AUTOSAR XML (schema 00046)
package /ComponentTypes
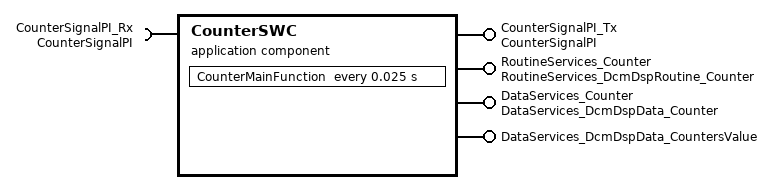
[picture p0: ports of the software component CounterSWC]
  application sw component type CounterSWC
    require port CounterSignalPI_Rx: nonqueued-receiver-com-spec{data-element=Element, filter=data-filter-type=ALWAYS, init-value=0}, required-interface=CounterSignalPI
    4 x provide port:
      CounterSignalPI_Tx: nonqueued-sender-com-spec{data-element=Element, init-value=0}, provided-interface=CounterSignalPI
      RoutineServices_Counter: provided-interface=RoutineServices_DcmDspRoutine_Counter
        provided-com-specs:
          operation=RequestResults, queue-length=1
          operation=Stop, queue-length=1
          operation=Start, queue-length=1
      DataServices_Counter: provided-com-specs=[{operation=WriteData, queue-length=1}, {operation=ReadData, queue-length=1}], provided-interface=DataServices_DcmDspData_Counter
      DataServices_DcmDspData_CountersValue: server-com-spec{operation=ReadData, queue-length=1}, provided-interface=DataServices_DcmDspData_CountersValue
    behavior CounterSWC_InternalBehavior
      data received event DRT_CounterRecieveSignal_CounterSignalPI_Rx_Element: start-on-event=CounterRecieveSignal, data=CounterSignalPI_Rx.Element
      timing event TMT_CounterMainFunction: start-on-event=CounterMainFunction, period=0.025
      6 x operation invoked event:
        OIT_RoutineServices_Counter_RequestResults_RoutineServices_Counter_RequestResults: start-on-event=RoutineServices_Counter_RequestResults, operation=RoutineServices_Counter.RequestResults
        OIT_RoutineServices_Counter_Stop_RoutineServices_Counter_Stop: start-on-event=RoutineServices_Counter_Stop, operation=RoutineServices_Counter.Stop
        OIT_RoutineServices_Counter_Start_RoutineServices_Counter_Start: start-on-event=RoutineServices_Counter_Start, operation=RoutineServices_Counter.Start
        OIT_DataServices_Counter_WriteData_DataServices_Counter_WriteData: start-on-event=DataServices_Counter_WriteData, operation=DataServices_Counter.WriteData
        OIT_DataServices_Counter_ReadData_DataServices_Counter_ReadData: start-on-event=DataServices_Counter_ReadData, operation=DataServices_Counter.ReadData
        OIT_DataServices_DcmDspData_CountersValue_ReadData_DataServices_DcmDspData_CountersValue_ReadData: start-on-event=DataServices_DcmDspData_CountersValue_ReadData, operation=DataServices_DcmDspData_CountersValue.ReadData
      explicit-inter-runnable-variables:
        data CounterValueIRV: type=uint16, init-value=0
      8 x runnable:
        CounterRecieveSignal
          data-receive-point-by-arguments:
            access REC_CounterSignalPI_Rx_Element: accessed-variable=CounterSignalPI_Rx.Element
          written-local-variables:
            access WRITE_CounterValueIRV: accessed-variable=CounterValueIRV
        CounterMainFunction
          data-send-points:
            access SEND_CounterSignalPI_Tx_Element: accessed-variable=CounterSignalPI_Tx.Element
          read-local-variables:
            access Read_CounterValueIRV: accessed-variable=CounterValueIRV
          written-local-variables:
            access WRITE_CounterValueIRV: accessed-variable=CounterValueIRV
        RoutineServices_Counter_RequestResults
        RoutineServices_Counter_Stop
        RoutineServices_Counter_Start
        DataServices_Counter_WriteData
          written-local-variables:
            access WRITE_CounterValueIRV: accessed-variable=CounterValueIRV
        DataServices_Counter_ReadData
          read-local-variables:
            access Read_CounterValueIRV: accessed-variable=CounterValueIRV
        DataServices_DcmDspData_CountersValue_ReadData
  swc implementation CounterSWC_Implementation: behavior=CounterSWC_InternalBehavior
